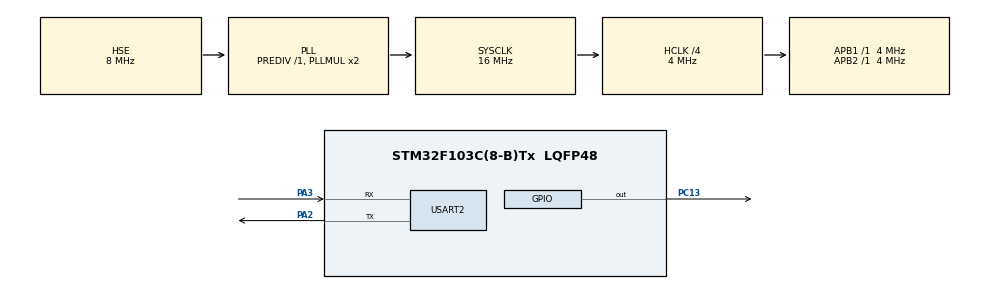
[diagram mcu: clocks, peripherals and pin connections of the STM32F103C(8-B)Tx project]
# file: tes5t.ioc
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Dma.Request0=USART2_RX
Dma.USART2_RX.0.Direction=DMA_PERIPH_TO_MEMORY
Dma.USART2_RX.0.Instance=DMA1_Channel6
Dma.USART2_RX.0.MemDataAlignment=DMA_MDATAALIGN_BYTE
Dma.USART2_RX.0.MemInc=DMA_MINC_ENABLE
Dma.USART2_RX.0.Mode=DMA_NORMAL
Dma.USART2_RX.0.PeriphDataAlignment=DMA_PDATAALIGN_BYTE
Dma.USART2_RX.0.PeriphInc=DMA_PINC_DISABLE
Dma.USART2_RX.0.Priority=DMA_PRIORITY_LOW
Mcu.Family=STM32F1
Mcu.Name=STM32F103C(8-B)Tx
Mcu.Package=LQFP48
NVIC.DMA1_Channel6_IRQn=true\:0\:0\:false\:false\:true\:false\:true
NVIC.PriorityGroup=NVIC_PRIORITYGROUP_4
NVIC.USART2_IRQn=true\:0\:0\:false\:false\:true\:true\:true
PA13.Mode=Serial_Wire
PA13.Signal=SYS_JTMS-SWDIO
PA14.Mode=Serial_Wire
PA14.Signal=SYS_JTCK-SWCLK
PA2.Mode=Asynchronous
PA2.Signal=USART2_TX
PA3.Mode=Asynchronous
PA3.Signal=USART2_RX
PC13-TAMPER-RTC.Signal=GPIO_Output
PD0-OSC_IN.Mode=HSE-External-Oscillator
PD0-OSC_IN.Signal=RCC_OSC_IN
PD1-OSC_OUT.Mode=HSE-External-Oscillator
PD1-OSC_OUT.Signal=RCC_OSC_OUT
ProjectManager.HeapSize=0x200
ProjectManager.StackSize=0x400
ProjectManager.TargetToolchain=STM32CubeIDE
RCC.AHBCLKDivider=RCC_SYSCLK_DIV4
RCC.AHBFreq_Value=4000000
RCC.APB1Freq_Value=4000000
RCC.APB1TimFreq_Value=4000000
RCC.APB2Freq_Value=4000000
RCC.APB2TimFreq_Value=4000000
RCC.HCLKFreq_Value=4000000
RCC.PLLSourceVirtual=RCC_PLLSOURCE_HSE
RCC.SYSCLKFreq_VALUE=16000000
RCC.SYSCLKSource=RCC_SYSCLKSOURCE_PLLCLK
RCC.USBFreq_Value=16000000
USART2.VirtualMode=VM_ASYNC
board=custom

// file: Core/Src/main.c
/* USER CODE BEGIN Header */
/**
 ******************************************************************************
 * @file           : main.c
 * @brief          : Main program body
 ******************************************************************************
 * @attention
 *
 * <h2><center>&copy; Copyright (c) 2026 STMicroelectronics.
 * All rights reserved.</center></h2>
 *
 * This software component is licensed by ST under BSD 3-Clause license,
 * the "License"; You may not use this file except in compliance with the
 * License. You may obtain a copy of the License at:
 *                        opensource.org/licenses/BSD-3-Clause
 *
 ******************************************************************************
 */
/* USER CODE END Header */
#include "main.h"

/* USER CODE BEGIN Includes */
#include <stdio.h>
#include <string.h>
/* USER CODE END Includes */

UART_HandleTypeDef huart2;
DMA_HandleTypeDef hdma_usart2_rx;

/* USER CODE BEGIN PV */
uint8_t rxData;
uint8_t led_op;
int rx_flag = 0;
/* USER CODE END PV */

void SystemClock_Config(void);
static void MX_GPIO_Init(void);
static void MX_USART2_UART_Init(void);
static void MX_DMA_Init(void);

int main(void)
{

  /* MCU Configuration--------------------------------------------------------*/

  /* Reset of all peripherals, Initializes the Flash interface and the Systick. */
  HAL_Init();

  /* Configure the system clock */
  SystemClock_Config();

  /* Initialize all configured peripherals */
  MX_GPIO_Init();
  MX_DMA_Init();
  MX_USART2_UART_Init();
  /* USER CODE BEGIN 2 */

	/* Start UART interrupt reception */
	HAL_UART_Receive_DMA(&huart2, &rxData, 1);

	char startMsg[] = "UART Interrupt Started\r\n";
	HAL_UART_Transmit(&huart2, (uint8_t*) startMsg, strlen(startMsg), 100);

  /* USER CODE END 2 */

  /* Infinite loop */
  /* USER CODE BEGIN WHILE */
	while (1) {
		if (rx_flag == 1) {
			rx_flag = 0;
			/* If received character is '0' */
			if (rxData == '0') {
				HAL_GPIO_WritePin(GPIOC, GPIO_PIN_13, GPIO_PIN_SET);

				char msg[] = "LED OFF\r\n";
				HAL_UART_Transmit(&huart2, (uint8_t*) msg, strlen(msg), 100);
			}

			/* If received character is '1' */
			else if (rxData == '1') {
				HAL_GPIO_WritePin(GPIOC, GPIO_PIN_13, GPIO_PIN_RESET);

				char msg[] = "LED ON\r\n";
				HAL_UART_Transmit(&huart2, (uint8_t*) msg, strlen(msg), 100);
			}

			/* Echo any other character */
			else {
				HAL_UART_Transmit(&huart2, &rxData, 1, 100);
			}

			/* Restart interrupt reception */
			HAL_UART_Receive_DMA(&huart2, &rxData, 1);
		}

    /* USER CODE END WHILE */

	}
}

void SystemClock_Config(void)
{
  RCC_OscInitTypeDef RCC_OscInitStruct = {0};
  RCC_ClkInitTypeDef RCC_ClkInitStruct = {0};

  /** Initializes the RCC Oscillators according to the specified parameters
  * in the RCC_OscInitTypeDef structure.
  */
  RCC_OscInitStruct.OscillatorType = RCC_OSCILLATORTYPE_HSE;
  RCC_OscInitStruct.HSEState = RCC_HSE_ON;
  RCC_OscInitStruct.HSEPredivValue = RCC_HSE_PREDIV_DIV1;
  RCC_OscInitStruct.HSIState = RCC_HSI_ON;
  RCC_OscInitStruct.PLL.PLLState = RCC_PLL_ON;
  RCC_OscInitStruct.PLL.PLLSource = RCC_PLLSOURCE_HSE;
  RCC_OscInitStruct.PLL.PLLMUL = RCC_PLL_MUL2;
  if (HAL_RCC_OscConfig(&RCC_OscInitStruct) != HAL_OK)
  {
    Error_Handler();
  }
  /** Initializes the CPU, AHB and APB buses clocks
  */
  RCC_ClkInitStruct.ClockType = RCC_CLOCKTYPE_HCLK|RCC_CLOCKTYPE_SYSCLK
                              |RCC_CLOCKTYPE_PCLK1|RCC_CLOCKTYPE_PCLK2;
  RCC_ClkInitStruct.SYSCLKSource = RCC_SYSCLKSOURCE_PLLCLK;
  RCC_ClkInitStruct.AHBCLKDivider = RCC_SYSCLK_DIV4;
  RCC_ClkInitStruct.APB1CLKDivider = RCC_HCLK_DIV1;
  RCC_ClkInitStruct.APB2CLKDivider = RCC_HCLK_DIV1;

  if (HAL_RCC_ClockConfig(&RCC_ClkInitStruct, FLASH_LATENCY_0) != HAL_OK)
  {
    Error_Handler();
  }
}

static void MX_USART2_UART_Init(void)
{

  huart2.Instance = USART2;
  huart2.Init.BaudRate = 115200;
  huart2.Init.WordLength = UART_WORDLENGTH_8B;
  huart2.Init.StopBits = UART_STOPBITS_1;
  huart2.Init.Parity = UART_PARITY_NONE;
  huart2.Init.Mode = UART_MODE_TX_RX;
  huart2.Init.HwFlowCtl = UART_HWCONTROL_NONE;
  huart2.Init.OverSampling = UART_OVERSAMPLING_16;
  if (HAL_UART_Init(&huart2) != HAL_OK)
  {
    Error_Handler();
  }

}

static void MX_DMA_Init(void)
{

  /* DMA controller clock enable */
  __HAL_RCC_DMA1_CLK_ENABLE();

  /* DMA interrupt init */
  /* DMA1_Channel6_IRQn interrupt configuration */
  HAL_NVIC_SetPriority(DMA1_Channel6_IRQn, 0, 0);
  HAL_NVIC_EnableIRQ(DMA1_Channel6_IRQn);

}

static void MX_GPIO_Init(void)
{
  GPIO_InitTypeDef GPIO_InitStruct = {0};

  /* GPIO Ports Clock Enable */
  __HAL_RCC_GPIOC_CLK_ENABLE();
  __HAL_RCC_GPIOD_CLK_ENABLE();
  __HAL_RCC_GPIOA_CLK_ENABLE();

  /*Configure GPIO pin Output Level */
  HAL_GPIO_WritePin(GPIOC, GPIO_PIN_13, GPIO_PIN_RESET);

  /*Configure GPIO pin : PC13 */
  GPIO_InitStruct.Pin = GPIO_PIN_13;
  GPIO_InitStruct.Mode = GPIO_MODE_OUTPUT_PP;
  GPIO_InitStruct.Pull = GPIO_NOPULL;
  GPIO_InitStruct.Speed = GPIO_SPEED_FREQ_LOW;
  HAL_GPIO_Init(GPIOC, &GPIO_InitStruct);

}

/* USER CODE BEGIN 4 */
void HAL_UART_RxCpltCallback(UART_HandleTypeDef *huart)
{
    if (huart == &huart2)
    {
        rx_flag = 1;
    }
}

/**
 * @brief UART Receive Complete Callback
 * This function runs automatically after UART interrupt
 */

/* USER CODE END 4 */

void Error_Handler(void)
{
	__disable_irq();
	while (1) {
	}
}

/************************ (C) COPYRIGHT STMicroelectronics *****END OF FILE****/
